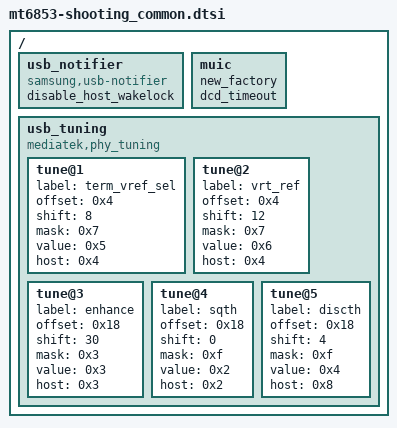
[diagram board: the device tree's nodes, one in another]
/* Generated by Samsung for MTK vendor board 
 * If these files should be changed, then please make a sync with MTK
*/

#include "display_lcd_shooting_common.dtsi"

/* Add Samsung configuration over here */
/ {
	fragment@model {
		target-path = "/";
		__overlay__ {
			usb_notifier {
				compatible = "samsung,usb-notifier";
				disable_host_wakelock;
			};
			muic {
				new_factory;
				dcd_timeout;
			};
			usb_tuning:usb_tuning {
				compatible = "mediatek,phy_tuning";

				tune@1 {
					label = "term_vref_sel";
					offset = <0x4>;
					shift = <8>;
					mask = <0x7>;
					value = <0x5>;
					host = <0x4>;
				};

				tune@2 {
					label = "vrt_ref";
					offset = <0x4>;
					shift = <12>;
					mask = <0x7>;
					value = <0x6>;
					host = <0x4>;
				};

				tune@3 {
					label = "enhance";
					offset = <0x18>;
					shift = <30>;
					mask = <0x3>;
					value = <0x3>;
					host = <0x3>;
				};

				tune@4 {
					label = "sqth";
					offset = <0x18>;
					shift = <0>;
					mask = <0xf>;
					value = <0x2>;
					host = <0x2>;
				};

				tune@5 {
					label = "discth";
					offset = <0x18>;
					shift = <4>;
					mask = <0xf>;
					value = <0x4>;
					host = <0x8>;
				};
			};
		};
	};
};
